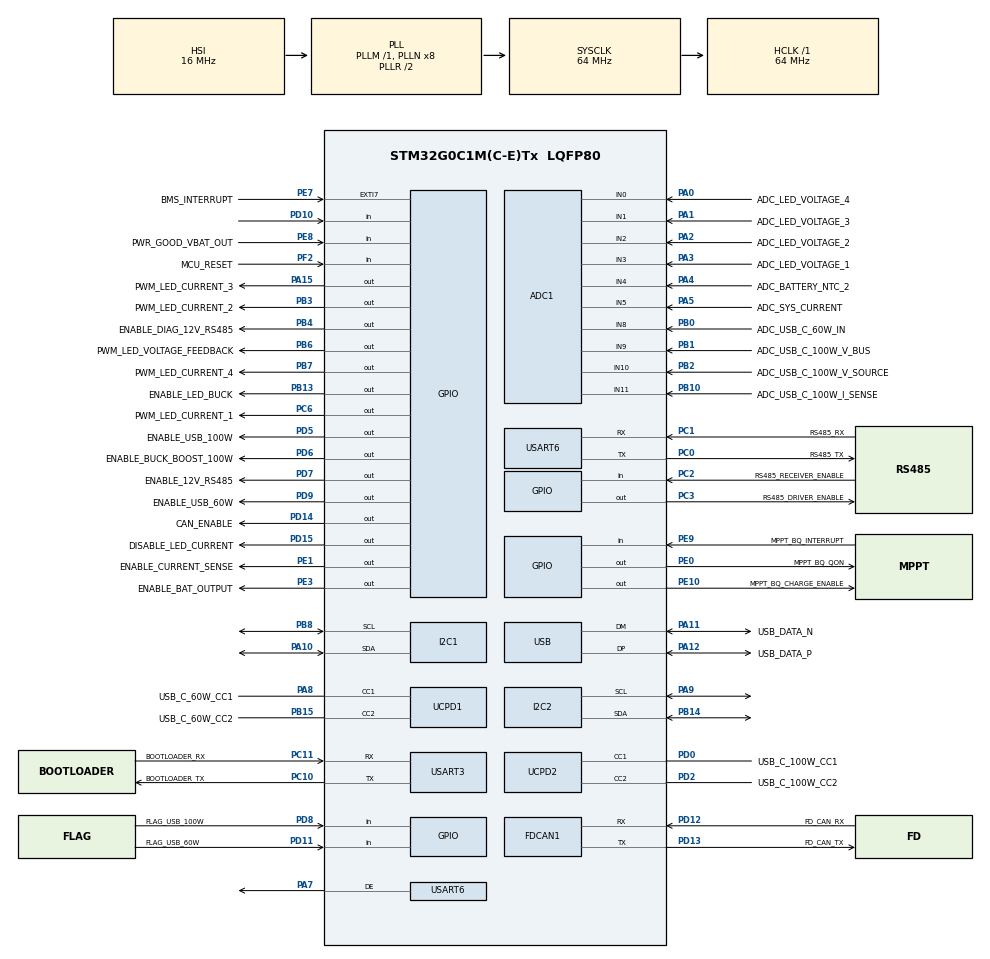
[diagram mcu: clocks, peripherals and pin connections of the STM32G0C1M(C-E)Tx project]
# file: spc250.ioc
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ADC1.DMAContinuousRequests=ENABLE
ADC1.ExternalTrigConv=ADC_EXTERNALTRIG_T4_TRGO
ADC1.ExternalTrigConvEdge=ADC_EXTERNALTRIGCONVEDGE_RISING
ADC1.NbrOfConversionFlag=1
ADC1.SelectedChannel=ADC_CHANNEL_0|ADC_CHANNEL_1|ADC_CHANNEL_2|ADC_CHANNEL_3|ADC_CHANNEL_4|ADC_CHANNEL_5|ADC_CHANNEL_8|ADC_CHANNEL_9|ADC_CHANNEL_10|ADC_CHANNEL_11
ADC1.master=1
Dma.ADC1.0.Direction=DMA_PERIPH_TO_MEMORY
Dma.ADC1.0.EventEnable=DISABLE
Dma.ADC1.0.Instance=DMA1_Channel1
Dma.ADC1.0.MemDataAlignment=DMA_MDATAALIGN_HALFWORD
Dma.ADC1.0.MemInc=DMA_MINC_ENABLE
Dma.ADC1.0.Mode=DMA_CIRCULAR
Dma.ADC1.0.PeriphDataAlignment=DMA_PDATAALIGN_HALFWORD
Dma.ADC1.0.PeriphInc=DMA_PINC_DISABLE
Dma.ADC1.0.Polarity=HAL_DMAMUX_REQ_GEN_RISING
Dma.ADC1.0.Priority=DMA_PRIORITY_LOW
Dma.ADC1.0.RequestNumber=1
Dma.ADC1.0.SignalID=NONE
Dma.ADC1.0.SyncEnable=DISABLE
Dma.ADC1.0.SyncPolarity=HAL_DMAMUX_SYNC_NO_EVENT
Dma.ADC1.0.SyncRequestNumber=1
Dma.ADC1.0.SyncSignalID=NONE
Dma.Request0=ADC1
FDCAN1.CalculateBaudRateNominal=1333333
FDCAN1.CalculateTimeBitNominal=750
FDCAN1.CalculateTimeQuantumNominal=250.0
I2C1.Timing=0x10B17DB5
I2C2.Timing=0x10B17DB5
Mcu.Family=STM32G0
Mcu.Name=STM32G0C1M(C-E)Tx
Mcu.Package=LQFP80
NVIC.DMA1_Channel1_IRQn=true\:0\:0\:false\:false\:true\:false\:true\:true
PA0.GPIO_Label=ADC_LED_VOLTAGE_4 
PA0.Mode=IN0
PA0.Signal=ADC1_IN0
PA1.GPIO_Label=ADC_LED_VOLTAGE_3
PA1.Mode=IN1
PA1.Signal=ADC1_IN1
PA10.Mode=I2C
PA10.Signal=I2C1_SDA
PA11\ [PA9].GPIO_Label=USB_DATA_N 
PA11\ [PA9].Mode=Device
PA11\ [PA9].Signal=USB_DM
PA12\ [PA10].GPIO_Label=USB_DATA_P 
PA12\ [PA10].Mode=Device
PA12\ [PA10].Signal=USB_DP
PA13.GPIO_Label=DEBUG_SWDIO 
PA13.Mode=Serial_Wire
PA13.Signal=SYS_SWDIO
PA14-BOOT0.GPIO_Label=DEBUG_SWCLK 
PA14-BOOT0.Mode=Serial_Wire
PA14-BOOT0.Signal=SYS_SWCLK
PA15.GPIO_Label=PWM_LED_CURRENT_3 
PA15.Signal=GPIO_Output
PA2.GPIO_Label=ADC_LED_VOLTAGE_2
PA2.Mode=IN2
PA2.Signal=ADC1_IN2
PA3.GPIO_Label=ADC_LED_VOLTAGE_1 
PA3.Mode=IN3
PA3.Signal=ADC1_IN3
PA4.GPIO_Label=ADC_BATTERY_NTC_2 
PA4.Mode=IN4
PA4.Signal=ADC1_IN4
PA5.GPIO_Label=ADC_SYS_CURRENT 
PA5.Mode=IN5
PA5.Signal=ADC1_IN5
PA7.Mode=Hardware Flow Control (RS485)
PA7.Signal=USART6_DE
PA8.GPIO_Label=USB_C_60W_CC1 
PA8.Mode=Source_AllSignals
PA8.Signal=UCPD1_CC1
PA9.Mode=I2C
PA9.Signal=I2C2_SCL
PB0.GPIO_Label=ADC_USB_C_60W_IN 
PB0.Mode=IN8
PB0.Signal=ADC1_IN8
PB1.GPIO_Label=ADC_USB_C_100W_V_BUS 
PB1.Mode=IN9
PB1.Signal=ADC1_IN9
PB10.GPIO_Label=ADC_USB_C_100W_I_SENSE 
PB10.Mode=IN11
PB10.Signal=ADC1_IN11
PB11.GPIO_Label=ADC_USB_C_100W_V_SINK 
PB11.Signal=ADC1_IN15
PB12.GPIO_Label=ADC_USB_C_60W_V_BUS
PB12.Signal=ADC1_IN16
PB13.GPIO_Label=ENABLE_LED_BUCK 
PB13.Signal=GPIO_Output
PB14.Mode=I2C
PB14.Signal=I2C2_SDA
PB15.GPIO_Label=USB_C_60W_CC2 
PB15.Mode=Source_AllSignals
PB15.Signal=UCPD1_CC2
PB2.GPIO_Label=ADC_USB_C_100W_V_SOURCE 
PB2.Mode=IN10
PB2.Signal=ADC1_IN10
PB3.GPIO_Label=PWM_LED_CURRENT_2 
PB3.Signal=GPIO_Output
PB4.GPIO_Label=ENABLE_DIAG_12V_RS485 
PB4.Signal=GPIO_Output
PB6.GPIO_Label=PWM_LED_VOLTAGE_FEEDBACK 
PB6.Signal=GPIO_Output
PB7.GPIO_Label=PWM_LED_CURRENT_4 
PB7.Signal=GPIO_Output
PB8.Mode=I2C
PB8.Signal=I2C1_SCL
PC0.GPIO_Label=RS485_TX 
PC0.Mode=Asynchronous
PC0.Signal=USART6_TX
PC1.GPIO_Label=RS485_RX 
PC1.Mode=Asynchronous
PC1.Signal=USART6_RX
PC10.GPIO_Label=BOOTLOADER_TX 
PC10.Mode=Asynchronous
PC10.Signal=USART3_TX
PC11.GPIO_Label=BOOTLOADER_RX 
PC11.Mode=Asynchronous
PC11.Signal=USART3_RX
PC2.GPIO_Label=RS485_RECEIVER_ENABLE 
PC2.Signal=GPIO_Input
PC3.GPIO_Label=RS485_DRIVER_ENABLE 
PC3.Signal=GPIO_Output
PC4.GPIO_Label=ADC_USB_C_60W_I_SENSE
PC4.Signal=ADC1_IN17
PC5.GPIO_Label=ADC_USB_C_60W_V_SINK 
PC5.Signal=ADC1_IN18
PC6.GPIO_Label=PWM_LED_CURRENT_1 
PC6.Signal=GPIO_Output
PD0.GPIO_Label=USB_C_100W_CC1 
PD0.Mode=Source_AllSignals
PD0.Signal=UCPD2_CC1
PD10.Signal=GPIO_Input
PD11.GPIO_Label=FLAG_USB_60W 
PD11.Signal=GPIO_Input
PD12.GPIO_Label=FD_CAN_RX 
PD12.Mode=FDCAN_Activate
PD12.Signal=FDCAN1_RX
PD13.GPIO_Label=FD_CAN_TX 
PD13.Mode=FDCAN_Activate
PD13.Signal=FDCAN1_TX
PD14.GPIO_Label=CAN_ENABLE 
PD14.Signal=GPIO_Output
PD15.GPIO_Label=DISABLE_LED_CURRENT 
PD15.Signal=GPIO_Output
PD2.GPIO_Label=USB_C_100W_CC2 
PD2.Mode=Source_AllSignals
PD2.Signal=UCPD2_CC2
PD5.GPIO_Label=ENABLE_USB_100W 
PD5.Signal=GPIO_Output
PD6.GPIO_Label=ENABLE_BUCK_BOOST_100W 
PD6.Signal=GPIO_Output
PD7.GPIO_Label=ENABLE_12V_RS485 
PD7.Signal=GPIO_Output
PD8.GPIO_Label=FLAG_USB_100W 
PD8.Signal=GPIO_Input
PD9.GPIO_Label=ENABLE_USB_60W 
PD9.Signal=GPIO_Output
PE0.GPIO_Label=MPPT_BQ_QON 
PE0.Signal=GPIO_Output
PE1.GPIO_Label=ENABLE_CURRENT_SENSE 
PE1.Signal=GPIO_Output
PE10.GPIO_Label=MPPT_BQ_CHARGE_ENABLE 
PE10.Signal=GPIO_Output
PE3.GPIO_Label=ENABLE_BAT_OUTPUT 
PE3.Signal=GPIO_Output
PE7.GPIO_Label=BMS_INTERRUPT 
PE7.Signal=GPXTI7
PE8.GPIO_Label=PWR_GOOD_VBAT_OUT 
PE8.Signal=GPIO_Input
PE9.GPIO_Label=MPPT_BQ_INTERRUPT 
PE9.Signal=GPIO_Input
PF2-NRST.GPIO_Label=MCU_RESET 
PF2-NRST.Signal=GPIO_Input
ProjectManager.HeapSize=0x200
ProjectManager.StackSize=0x400
ProjectManager.TargetToolchain=STM32CubeIDE
RCC.ADCFreq_Value=64000000
RCC.AHBFreq_Value=64000000
RCC.CortexFreq_Value=64000000
RCC.EXTERNAL_CLOCK_VALUE=48000
RCC.HCLKFreq_Value=64000000
RCC.HSE_VALUE=8000000
RCC.HSI48_VALUE=48000000
RCC.HSI_VALUE=16000000
RCC.LSE_VALUE=32768
RCC.SYSCLKFreq_VALUE=64000000
RCC.SYSCLKSource=RCC_SYSCLKSOURCE_PLLCLK
RCC.USBFreq_Value=48000000
RCC.VCOOutputFreq_Value=128000000
TIM4.Period=1000-1
TIM4.Prescaler=6400-1
TIM4.TIM_MasterOutputTrigger=TIM_TRGO_UPDATE
USART3.VirtualMode-Asynchronous=VM_ASYNC
USART6.VirtualMode-Asynchronous=VM_ASYNC
USART6.VirtualMode-Hardware\ Flow\ Control\ (RS485)=VM_ASYNC
VP_SYS_VS_DBSignals.Mode=DisableDeadBatterySignals
VP_TIM4_VS_ClockSourceINT.Mode=Internal
board=custom

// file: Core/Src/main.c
/* USER CODE BEGIN Header */
/**
  ******************************************************************************
  * @file           : main.c
  * @brief          : Main program body
  ******************************************************************************
  * @attention
  *
  * Copyright (c) 2025 STMicroelectronics.
  * All rights reserved.
  *
  * This software is licensed under terms that can be found in the LICENSE file
  * in the root directory of this software component.
  * If no LICENSE file comes with this software, it is provided AS-IS.
  *
  ******************************************************************************
  */
/* USER CODE END Header */
#include "main.h"

/* USER CODE BEGIN PD */
#define ADC_NUM_CONVERSIONS 17
/* USER CODE END PD */

ADC_HandleTypeDef hadc1;
DMA_HandleTypeDef hdma_adc1;

FDCAN_HandleTypeDef hfdcan1;

I2C_HandleTypeDef hi2c1;
I2C_HandleTypeDef hi2c2;

TIM_HandleTypeDef htim4;

UART_HandleTypeDef huart3;
UART_HandleTypeDef huart6;

PCD_HandleTypeDef hpcd_USB_DRD_FS;

/* USER CODE BEGIN PV */
uint16_t adc_buffer[ADC_NUM_CONVERSIONS]; // buffer to store ADC values
/* USER CODE END PV */

void SystemClock_Config(void);
static void MX_GPIO_Init(void);
static void MX_DMA_Init(void);
static void MX_ADC1_Init(void);
static void MX_TIM4_Init(void);
static void MX_FDCAN1_Init(void);
static void MX_I2C1_Init(void);
static void MX_I2C2_Init(void);
static void MX_UCPD1_Init(void);
static void MX_UCPD2_Init(void);
static void MX_USART3_UART_Init(void);
static void MX_USART6_UART_Init(void);
static void MX_USB_DRD_FS_PCD_Init(void);

int main(void)
{

  /* MCU Configuration--------------------------------------------------------*/

  /* Reset of all peripherals, Initializes the Flash interface and the Systick. */
  HAL_Init();

  /* Configure the system clock */
  SystemClock_Config();

  /* Initialize all configured peripherals */
  MX_GPIO_Init();
  MX_DMA_Init();
  MX_ADC1_Init();
  MX_TIM4_Init();
  MX_FDCAN1_Init();
  MX_I2C1_Init();
  MX_I2C2_Init();
  MX_UCPD1_Init();
  MX_UCPD2_Init();
  MX_USART3_UART_Init();
  MX_USART6_UART_Init();
  MX_USB_DRD_FS_PCD_Init();
  /* USER CODE BEGIN 2 */
  HAL_ADCEx_Calibration_GetValue(&hadc1); // caibrate the ADC
  HAL_ADC_Start_DMA(&hadc1, (uint32_t*)adc_buffer, ADC_NUM_CONVERSIONS); // start ADC in DMA mode to fill buffer 10 times a second
  HAL_TIM_Base_Start(&htim4); // start timer 4
  /* USER CODE END 2 */

  /* Infinite loop */
  while (1)
  {

  }
}

void SystemClock_Config(void)
{
  RCC_OscInitTypeDef RCC_OscInitStruct = {0};
  RCC_ClkInitTypeDef RCC_ClkInitStruct = {0};

  /** Configure the main internal regulator output voltage
  */
  HAL_PWREx_ControlVoltageScaling(PWR_REGULATOR_VOLTAGE_SCALE1);

  /** Initializes the RCC Oscillators according to the specified parameters
  * in the RCC_OscInitTypeDef structure.
  */
  RCC_OscInitStruct.OscillatorType = RCC_OSCILLATORTYPE_HSI|RCC_OSCILLATORTYPE_HSI48;
  RCC_OscInitStruct.HSIState = RCC_HSI_ON;
  RCC_OscInitStruct.HSI48State = RCC_HSI48_ON;
  RCC_OscInitStruct.HSIDiv = RCC_HSI_DIV1;
  RCC_OscInitStruct.HSICalibrationValue = RCC_HSICALIBRATION_DEFAULT;
  RCC_OscInitStruct.PLL.PLLState = RCC_PLL_ON;
  RCC_OscInitStruct.PLL.PLLSource = RCC_PLLSOURCE_HSI;
  RCC_OscInitStruct.PLL.PLLM = RCC_PLLM_DIV1;
  RCC_OscInitStruct.PLL.PLLN = 8;
  RCC_OscInitStruct.PLL.PLLP = RCC_PLLP_DIV2;
  RCC_OscInitStruct.PLL.PLLQ = RCC_PLLQ_DIV2;
  RCC_OscInitStruct.PLL.PLLR = RCC_PLLR_DIV2;
  if (HAL_RCC_OscConfig(&RCC_OscInitStruct) != HAL_OK)
  {
    Error_Handler();
  }

  /** Initializes the CPU, AHB and APB buses clocks
  */
  RCC_ClkInitStruct.ClockType = RCC_CLOCKTYPE_HCLK|RCC_CLOCKTYPE_SYSCLK
                              |RCC_CLOCKTYPE_PCLK1;
  RCC_ClkInitStruct.SYSCLKSource = RCC_SYSCLKSOURCE_PLLCLK;
  RCC_ClkInitStruct.AHBCLKDivider = RCC_SYSCLK_DIV1;
  RCC_ClkInitStruct.APB1CLKDivider = RCC_HCLK_DIV1;

  if (HAL_RCC_ClockConfig(&RCC_ClkInitStruct, FLASH_LATENCY_2) != HAL_OK)
  {
    Error_Handler();
  }
}

static void MX_ADC1_Init(void)
{

  /** Configure the global features of the ADC (Clock, Resolution, Data Alignment and number of conversion)
  */
  hadc1.Instance = ADC1;
  hadc1.Init.ClockPrescaler = ADC_CLOCK_SYNC_PCLK_DIV2;
  hadc1.Init.Resolution = ADC_RESOLUTION_12B;
  hadc1.Init.DataAlign = ADC_DATAALIGN_RIGHT;
  hadc1.Init.ScanConvMode = ADC_SCAN_DISABLE;
  hadc1.Init.EOCSelection = ADC_EOC_SINGLE_CONV;
  hadc1.Init.LowPowerAutoWait = DISABLE;
  hadc1.Init.LowPowerAutoPowerOff = DISABLE;
  hadc1.Init.ContinuousConvMode = DISABLE;
  hadc1.Init.NbrOfConversion = 1;
  hadc1.Init.DiscontinuousConvMode = DISABLE;
  hadc1.Init.ExternalTrigConv = ADC_EXTERNALTRIG_T4_TRGO;
  hadc1.Init.ExternalTrigConvEdge = ADC_EXTERNALTRIGCONVEDGE_RISING;
  hadc1.Init.DMAContinuousRequests = ENABLE;
  hadc1.Init.Overrun = ADC_OVR_DATA_PRESERVED;
  hadc1.Init.SamplingTimeCommon1 = ADC_SAMPLETIME_1CYCLE_5;
  hadc1.Init.SamplingTimeCommon2 = ADC_SAMPLETIME_1CYCLE_5;
  hadc1.Init.OversamplingMode = DISABLE;
  hadc1.Init.TriggerFrequencyMode = ADC_TRIGGER_FREQ_HIGH;
  if (HAL_ADC_Init(&hadc1) != HAL_OK)
  {
    Error_Handler();
  }

}

static void MX_FDCAN1_Init(void)
{

  hfdcan1.Instance = FDCAN1;
  hfdcan1.Init.ClockDivider = FDCAN_CLOCK_DIV1;
  hfdcan1.Init.FrameFormat = FDCAN_FRAME_CLASSIC;
  hfdcan1.Init.Mode = FDCAN_MODE_NORMAL;
  hfdcan1.Init.AutoRetransmission = DISABLE;
  hfdcan1.Init.TransmitPause = DISABLE;
  hfdcan1.Init.ProtocolException = DISABLE;
  hfdcan1.Init.NominalPrescaler = 16;
  hfdcan1.Init.NominalSyncJumpWidth = 1;
  hfdcan1.Init.NominalTimeSeg1 = 1;
  hfdcan1.Init.NominalTimeSeg2 = 1;
  hfdcan1.Init.DataPrescaler = 1;
  hfdcan1.Init.DataSyncJumpWidth = 1;
  hfdcan1.Init.DataTimeSeg1 = 1;
  hfdcan1.Init.DataTimeSeg2 = 1;
  hfdcan1.Init.StdFiltersNbr = 0;
  hfdcan1.Init.ExtFiltersNbr = 0;
  hfdcan1.Init.TxFifoQueueMode = FDCAN_TX_FIFO_OPERATION;
  if (HAL_FDCAN_Init(&hfdcan1) != HAL_OK)
  {
    Error_Handler();
  }

}

static void MX_I2C1_Init(void)
{

  hi2c1.Instance = I2C1;
  hi2c1.Init.Timing = 0x10B17DB5;
  hi2c1.Init.OwnAddress1 = 0;
  hi2c1.Init.AddressingMode = I2C_ADDRESSINGMODE_7BIT;
  hi2c1.Init.DualAddressMode = I2C_DUALADDRESS_DISABLE;
  hi2c1.Init.OwnAddress2 = 0;
  hi2c1.Init.OwnAddress2Masks = I2C_OA2_NOMASK;
  hi2c1.Init.GeneralCallMode = I2C_GENERALCALL_DISABLE;
  hi2c1.Init.NoStretchMode = I2C_NOSTRETCH_DISABLE;
  if (HAL_I2C_Init(&hi2c1) != HAL_OK)
  {
    Error_Handler();
  }

  /** Configure Analogue filter
  */
  if (HAL_I2CEx_ConfigAnalogFilter(&hi2c1, I2C_ANALOGFILTER_ENABLE) != HAL_OK)
  {
    Error_Handler();
  }

  /** Configure Digital filter
  */
  if (HAL_I2CEx_ConfigDigitalFilter(&hi2c1, 0) != HAL_OK)
  {
    Error_Handler();
  }

}

static void MX_I2C2_Init(void)
{

  hi2c2.Instance = I2C2;
  hi2c2.Init.Timing = 0x10B17DB5;
  hi2c2.Init.OwnAddress1 = 0;
  hi2c2.Init.AddressingMode = I2C_ADDRESSINGMODE_7BIT;
  hi2c2.Init.DualAddressMode = I2C_DUALADDRESS_DISABLE;
  hi2c2.Init.OwnAddress2 = 0;
  hi2c2.Init.OwnAddress2Masks = I2C_OA2_NOMASK;
  hi2c2.Init.GeneralCallMode = I2C_GENERALCALL_DISABLE;
  hi2c2.Init.NoStretchMode = I2C_NOSTRETCH_DISABLE;
  if (HAL_I2C_Init(&hi2c2) != HAL_OK)
  {
    Error_Handler();
  }

  /** Configure Analogue filter
  */
  if (HAL_I2CEx_ConfigAnalogFilter(&hi2c2, I2C_ANALOGFILTER_ENABLE) != HAL_OK)
  {
    Error_Handler();
  }

  /** Configure Digital filter
  */
  if (HAL_I2CEx_ConfigDigitalFilter(&hi2c2, 0) != HAL_OK)
  {
    Error_Handler();
  }

}

static void MX_TIM4_Init(void)
{

  TIM_ClockConfigTypeDef sClockSourceConfig = {0};
  TIM_MasterConfigTypeDef sMasterConfig = {0};

  htim4.Instance = TIM4;
  htim4.Init.Prescaler = 6400-1;
  htim4.Init.CounterMode = TIM_COUNTERMODE_UP;
  htim4.Init.Period = 1000-1;
  htim4.Init.ClockDivision = TIM_CLOCKDIVISION_DIV1;
  htim4.Init.AutoReloadPreload = TIM_AUTORELOAD_PRELOAD_DISABLE;
  if (HAL_TIM_Base_Init(&htim4) != HAL_OK)
  {
    Error_Handler();
  }
  sClockSourceConfig.ClockSource = TIM_CLOCKSOURCE_INTERNAL;
  if (HAL_TIM_ConfigClockSource(&htim4, &sClockSourceConfig) != HAL_OK)
  {
    Error_Handler();
  }
  sMasterConfig.MasterOutputTrigger = TIM_TRGO_UPDATE;
  sMasterConfig.MasterSlaveMode = TIM_MASTERSLAVEMODE_DISABLE;
  if (HAL_TIMEx_MasterConfigSynchronization(&htim4, &sMasterConfig) != HAL_OK)
  {
    Error_Handler();
  }

}

static void MX_UCPD1_Init(void)
{

  LL_GPIO_InitTypeDef GPIO_InitStruct = {0};

  /* Peripheral clock enable */
  LL_APB1_GRP1_EnableClock(LL_APB1_GRP1_PERIPH_UCPD1);

  LL_IOP_GRP1_EnableClock(LL_IOP_GRP1_PERIPH_GPIOB);
  LL_IOP_GRP1_EnableClock(LL_IOP_GRP1_PERIPH_GPIOA);
  /**UCPD1 GPIO Configuration
  PB15   ------> UCPD1_CC2
  PA8   ------> UCPD1_CC1
  */
  GPIO_InitStruct.Pin = LL_GPIO_PIN_15;
  GPIO_InitStruct.Mode = LL_GPIO_MODE_ANALOG;
  GPIO_InitStruct.Pull = LL_GPIO_PULL_NO;
  LL_GPIO_Init(GPIOB, &GPIO_InitStruct);

  GPIO_InitStruct.Pin = LL_GPIO_PIN_8;
  GPIO_InitStruct.Mode = LL_GPIO_MODE_ANALOG;
  GPIO_InitStruct.Pull = LL_GPIO_PULL_NO;
  LL_GPIO_Init(GPIOA, &GPIO_InitStruct);

}

static void MX_UCPD2_Init(void)
{

  LL_GPIO_InitTypeDef GPIO_InitStruct = {0};

  /* Peripheral clock enable */
  LL_APB1_GRP1_EnableClock(LL_APB1_GRP1_PERIPH_UCPD2);

  LL_IOP_GRP1_EnableClock(LL_IOP_GRP1_PERIPH_GPIOD);
  /**UCPD2 GPIO Configuration
  PD0   ------> UCPD2_CC1
  PD2   ------> UCPD2_CC2
  */
  GPIO_InitStruct.Pin = LL_GPIO_PIN_0;
  GPIO_InitStruct.Mode = LL_GPIO_MODE_ANALOG;
  GPIO_InitStruct.Pull = LL_GPIO_PULL_NO;
  LL_GPIO_Init(GPIOD, &GPIO_InitStruct);

  GPIO_InitStruct.Pin = LL_GPIO_PIN_2;
  GPIO_InitStruct.Mode = LL_GPIO_MODE_ANALOG;
  GPIO_InitStruct.Pull = LL_GPIO_PULL_NO;
  LL_GPIO_Init(GPIOD, &GPIO_InitStruct);

}

static void MX_USART3_UART_Init(void)
{

  huart3.Instance = USART3;
  huart3.Init.BaudRate = 115200;
  huart3.Init.WordLength = UART_WORDLENGTH_8B;
  huart3.Init.StopBits = UART_STOPBITS_1;
  huart3.Init.Parity = UART_PARITY_NONE;
  huart3.Init.Mode = UART_MODE_TX_RX;
  huart3.Init.HwFlowCtl = UART_HWCONTROL_NONE;
  huart3.Init.OverSampling = UART_OVERSAMPLING_16;
  huart3.Init.OneBitSampling = UART_ONE_BIT_SAMPLE_DISABLE;
  huart3.Init.ClockPrescaler = UART_PRESCALER_DIV1;
  huart3.AdvancedInit.AdvFeatureInit = UART_ADVFEATURE_NO_INIT;
  if (HAL_UART_Init(&huart3) != HAL_OK)
  {
    Error_Handler();
  }
  if (HAL_UARTEx_SetTxFifoThreshold(&huart3, UART_TXFIFO_THRESHOLD_1_8) != HAL_OK)
  {
    Error_Handler();
  }
  if (HAL_UARTEx_SetRxFifoThreshold(&huart3, UART_RXFIFO_THRESHOLD_1_8) != HAL_OK)
  {
    Error_Handler();
  }
  if (HAL_UARTEx_DisableFifoMode(&huart3) != HAL_OK)
  {
    Error_Handler();
  }

}

static void MX_USART6_UART_Init(void)
{

  huart6.Instance = USART6;
  huart6.Init.BaudRate = 115200;
  huart6.Init.WordLength = UART_WORDLENGTH_8B;
  huart6.Init.StopBits = UART_STOPBITS_1;
  huart6.Init.Parity = UART_PARITY_NONE;
  huart6.Init.Mode = UART_MODE_TX_RX;
  huart6.Init.HwFlowCtl = UART_HWCONTROL_NONE;
  huart6.Init.OverSampling = UART_OVERSAMPLING_16;
  huart6.Init.OneBitSampling = UART_ONE_BIT_SAMPLE_DISABLE;
  huart6.Init.ClockPrescaler = UART_PRESCALER_DIV1;
  huart6.AdvancedInit.AdvFeatureInit = UART_ADVFEATURE_NO_INIT;
  if (HAL_RS485Ex_Init(&huart6, UART_DE_POLARITY_HIGH, 0, 0) != HAL_OK)
  {
    Error_Handler();
  }

}

static void MX_USB_DRD_FS_PCD_Init(void)
{

  hpcd_USB_DRD_FS.Instance = USB_DRD_FS;
  hpcd_USB_DRD_FS.Init.dev_endpoints = 8;
  hpcd_USB_DRD_FS.Init.Host_channels = 8;
  hpcd_USB_DRD_FS.Init.speed = PCD_SPEED_FULL;
  hpcd_USB_DRD_FS.Init.phy_itface = PCD_PHY_EMBEDDED;
  hpcd_USB_DRD_FS.Init.Sof_enable = DISABLE;
  hpcd_USB_DRD_FS.Init.low_power_enable = DISABLE;
  hpcd_USB_DRD_FS.Init.lpm_enable = DISABLE;
  hpcd_USB_DRD_FS.Init.battery_charging_enable = DISABLE;
  hpcd_USB_DRD_FS.Init.vbus_sensing_enable = DISABLE;
  hpcd_USB_DRD_FS.Init.bulk_doublebuffer_enable = DISABLE;
  hpcd_USB_DRD_FS.Init.iso_singlebuffer_enable = DISABLE;
  if (HAL_PCD_Init(&hpcd_USB_DRD_FS) != HAL_OK)
  {
    Error_Handler();
  }

}

static void MX_DMA_Init(void)
{

  /* DMA controller clock enable */
  __HAL_RCC_DMA1_CLK_ENABLE();

  /* DMA interrupt init */
  /* DMA1_Channel1_IRQn interrupt configuration */
  HAL_NVIC_SetPriority(DMA1_Channel1_IRQn, 0, 0);
  HAL_NVIC_EnableIRQ(DMA1_Channel1_IRQn);

}

static void MX_GPIO_Init(void)
{
  GPIO_InitTypeDef GPIO_InitStruct = {0};

  /* GPIO Ports Clock Enable */
  __HAL_RCC_GPIOC_CLK_ENABLE();
  __HAL_RCC_GPIOF_CLK_ENABLE();
  __HAL_RCC_GPIOA_CLK_ENABLE();
  __HAL_RCC_GPIOB_CLK_ENABLE();
  __HAL_RCC_GPIOE_CLK_ENABLE();
  __HAL_RCC_GPIOD_CLK_ENABLE();

  /*Configure GPIO pin Output Level */
  HAL_GPIO_WritePin(GPIOC, RS485_DRIVER_ENABLE_Pin|PWM_LED_CURRENT_1_Pin, GPIO_PIN_RESET);

  /*Configure GPIO pin Output Level */
  HAL_GPIO_WritePin(GPIOE, MPPT_BQ_CHARGE_ENABLE_Pin|MPPT_BQ_QON_Pin|ENABLE_CURRENT_SENSE_Pin|ENABLE_BAT_OUTPUT_Pin, GPIO_PIN_RESET);

  /*Configure GPIO pin Output Level */
  HAL_GPIO_WritePin(GPIOB, ENABLE_LED_BUCK_Pin|PWM_LED_CURRENT_2_Pin|ENABLE_DIAG_12V_RS485_Pin|PWM_LED_VOLTAGE_FEEDBACK_Pin
                          |PWM_LED_CURRENT_4_Pin, GPIO_PIN_RESET);

  /*Configure GPIO pin Output Level */
  HAL_GPIO_WritePin(GPIOD, ENABLE_USB_60W_Pin|CAN_ENABLE_Pin|DISABLE_LED_CURRENT_Pin|ENABLE_USB_100W_Pin
                          |ENABLE_BUCK_BOOST_100W_Pin|ENABLE_12V_RS485_Pin, GPIO_PIN_RESET);

  /*Configure GPIO pin Output Level */
  HAL_GPIO_WritePin(PWM_LED_CURRENT_3_GPIO_Port, PWM_LED_CURRENT_3_Pin, GPIO_PIN_RESET);

  /*Configure GPIO pin : MCU_RESET_Pin */
  GPIO_InitStruct.Pin = MCU_RESET_Pin;
  GPIO_InitStruct.Mode = GPIO_MODE_INPUT;
  GPIO_InitStruct.Pull = GPIO_NOPULL;
  HAL_GPIO_Init(MCU_RESET_GPIO_Port, &GPIO_InitStruct);

  /*Configure GPIO pin : RS485_RECEIVER_ENABLE_Pin */
  GPIO_InitStruct.Pin = RS485_RECEIVER_ENABLE_Pin;
  GPIO_InitStruct.Mode = GPIO_MODE_INPUT;
  GPIO_InitStruct.Pull = GPIO_NOPULL;
  HAL_GPIO_Init(RS485_RECEIVER_ENABLE_GPIO_Port, &GPIO_InitStruct);

  /*Configure GPIO pins : RS485_DRIVER_ENABLE_Pin PWM_LED_CURRENT_1_Pin */
  GPIO_InitStruct.Pin = RS485_DRIVER_ENABLE_Pin|PWM_LED_CURRENT_1_Pin;
  GPIO_InitStruct.Mode = GPIO_MODE_OUTPUT_PP;
  GPIO_InitStruct.Pull = GPIO_NOPULL;
  GPIO_InitStruct.Speed = GPIO_SPEED_FREQ_LOW;
  HAL_GPIO_Init(GPIOC, &GPIO_InitStruct);

  /*Configure GPIO pin : BMS_INTERRUPT_Pin */
  GPIO_InitStruct.Pin = BMS_INTERRUPT_Pin;
  GPIO_InitStruct.Mode = GPIO_MODE_IT_RISING;
  GPIO_InitStruct.Pull = GPIO_NOPULL;
  HAL_GPIO_Init(BMS_INTERRUPT_GPIO_Port, &GPIO_InitStruct);

  /*Configure GPIO pins : PWR_GOOD_VBAT_OUT_Pin MPPT_BQ_INTERRUPT_Pin */
  GPIO_InitStruct.Pin = PWR_GOOD_VBAT_OUT_Pin|MPPT_BQ_INTERRUPT_Pin;
  GPIO_InitStruct.Mode = GPIO_MODE_INPUT;
  GPIO_InitStruct.Pull = GPIO_NOPULL;
  HAL_GPIO_Init(GPIOE, &GPIO_InitStruct);

  /*Configure GPIO pins : MPPT_BQ_CHARGE_ENABLE_Pin MPPT_BQ_QON_Pin ENABLE_CURRENT_SENSE_Pin ENABLE_BAT_OUTPUT_Pin */
  GPIO_InitStruct.Pin = MPPT_BQ_CHARGE_ENABLE_Pin|MPPT_BQ_QON_Pin|ENABLE_CURRENT_SENSE_Pin|ENABLE_BAT_OUTPUT_Pin;
  GPIO_InitStruct.Mode = GPIO_MODE_OUTPUT_PP;
  GPIO_InitStruct.Pull = GPIO_NOPULL;
  GPIO_InitStruct.Speed = GPIO_SPEED_FREQ_LOW;
  HAL_GPIO_Init(GPIOE, &GPIO_InitStruct);

  /*Configure GPIO pins : ENABLE_LED_BUCK_Pin PWM_LED_CURRENT_2_Pin ENABLE_DIAG_12V_RS485_Pin PWM_LED_VOLTAGE_FEEDBACK_Pin
                           PWM_LED_CURRENT_4_Pin */
  GPIO_InitStruct.Pin = ENABLE_LED_BUCK_Pin|PWM_LED_CURRENT_2_Pin|ENABLE_DIAG_12V_RS485_Pin|PWM_LED_VOLTAGE_FEEDBACK_Pin
                          |PWM_LED_CURRENT_4_Pin;
  GPIO_InitStruct.Mode = GPIO_MODE_OUTPUT_PP;
  GPIO_InitStruct.Pull = GPIO_NOPULL;
  GPIO_InitStruct.Speed = GPIO_SPEED_FREQ_LOW;
  HAL_GPIO_Init(GPIOB, &GPIO_InitStruct);

  /*Configure GPIO pins : FLAG_USB_100W_Pin PD10 FLAG_USB_60W_Pin */
  GPIO_InitStruct.Pin = FLAG_USB_100W_Pin|GPIO_PIN_10|FLAG_USB_60W_Pin;
  GPIO_InitStruct.Mode = GPIO_MODE_INPUT;
  GPIO_InitStruct.Pull = GPIO_NOPULL;
  HAL_GPIO_Init(GPIOD, &GPIO_InitStruct);

  /*Configure GPIO pins : ENABLE_USB_60W_Pin CAN_ENABLE_Pin DISABLE_LED_CURRENT_Pin ENABLE_USB_100W_Pin
                           ENABLE_BUCK_BOOST_100W_Pin ENABLE_12V_RS485_Pin */
  GPIO_InitStruct.Pin = ENABLE_USB_60W_Pin|CAN_ENABLE_Pin|DISABLE_LED_CURRENT_Pin|ENABLE_USB_100W_Pin
                          |ENABLE_BUCK_BOOST_100W_Pin|ENABLE_12V_RS485_Pin;
  GPIO_InitStruct.Mode = GPIO_MODE_OUTPUT_PP;
  GPIO_InitStruct.Pull = GPIO_NOPULL;
  GPIO_InitStruct.Speed = GPIO_SPEED_FREQ_LOW;
  HAL_GPIO_Init(GPIOD, &GPIO_InitStruct);

  /*Configure GPIO pin : PWM_LED_CURRENT_3_Pin */
  GPIO_InitStruct.Pin = PWM_LED_CURRENT_3_Pin;
  GPIO_InitStruct.Mode = GPIO_MODE_OUTPUT_PP;
  GPIO_InitStruct.Pull = GPIO_NOPULL;
  GPIO_InitStruct.Speed = GPIO_SPEED_FREQ_LOW;
  HAL_GPIO_Init(PWM_LED_CURRENT_3_GPIO_Port, &GPIO_InitStruct);

}

void Error_Handler(void)
{
  __disable_irq();
  while (1)
  {
  }
}
